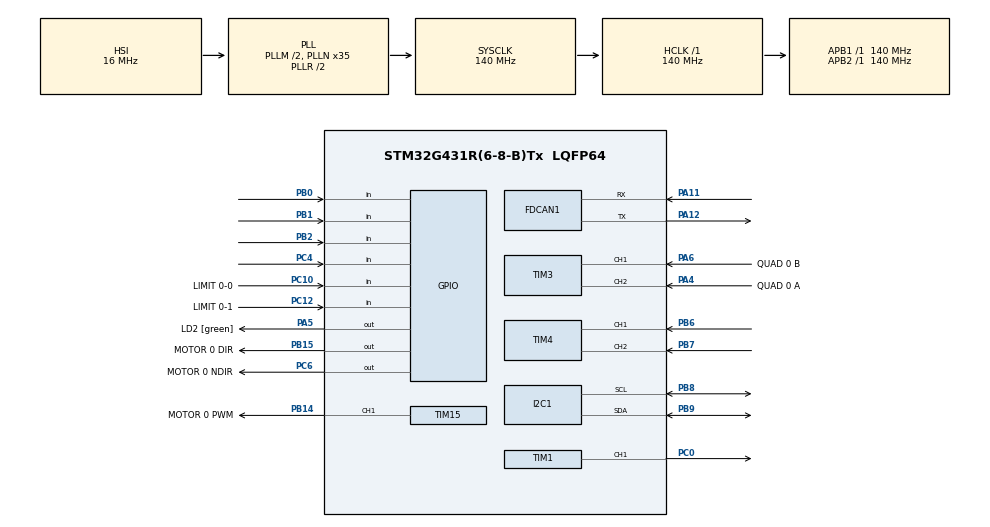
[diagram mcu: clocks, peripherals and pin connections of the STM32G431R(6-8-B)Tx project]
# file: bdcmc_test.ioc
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FDCAN1.CalculateBaudRateNominal=1000000
FDCAN1.CalculateTimeBitNominal=1000
FDCAN1.CalculateTimeQuantumNominal=7.142857142857143
FDCAN1.DataSyncJumpWidth=13
FDCAN1.DataTimeSeg1=14
FDCAN1.DataTimeSeg2=13
FDCAN1.FrameFormat=FDCAN_FRAME_FD_NO_BRS
FDCAN1.NominalPrescaler=1
FDCAN1.NominalSyncJumpWidth=19
FDCAN1.NominalTimeSeg1=120
FDCAN1.NominalTimeSeg2=19
I2C1.Timing=0x20B0CCFF
Mcu.Family=STM32G4
Mcu.Name=STM32G431R(6-8-B)Tx
Mcu.Package=LQFP64
NVIC.FDCAN1_IT0_IRQn=true\:0\:0\:false\:false\:true\:true\:true\:true
NVIC.I2C1_ER_IRQn=true\:0\:0\:false\:false\:true\:true\:true\:true
NVIC.I2C1_EV_IRQn=true\:0\:0\:false\:false\:true\:true\:true\:true
NVIC.PriorityGroup=NVIC_PRIORITYGROUP_4
NVIC.TIM1_TRG_COM_TIM17_IRQn=true\:0\:0\:false\:false\:true\:true\:true\:true
NVIC.TIM1_UP_TIM16_IRQn=true\:0\:0\:false\:false\:true\:true\:true\:true
NVIC.TIM3_IRQn=true\:0\:0\:false\:false\:true\:true\:true\:true
NVIC.TIM4_IRQn=true\:0\:0\:false\:false\:true\:true\:true\:true
NVIC.TIM6_DAC_IRQn=true\:0\:0\:false\:false\:true\:true\:true\:true
NVIC.TIM7_IRQn=true\:0\:0\:false\:false\:true\:true\:true\:true
PA11.Mode=FDCAN_Activate
PA11.Signal=FDCAN1_RX
PA12.Mode=FDCAN_Activate
PA12.Signal=FDCAN1_TX
PA13.GPIO_Label=T_SWDIO
PA13.Signal=SYS_JTMS-SWDIO
PA14.GPIO_Label=T_SWCLK
PA14.Signal=SYS_JTCK-SWCLK
PA2.GPIO_Label=LPUART1_TX [STLINKV3E_VCP_RX]
PA2.Signal=LPUART1_TX
PA3.GPIO_Label=LPUART1_RX [STLINKV3E_VCP_TX]
PA3.Signal=LPUART1_RX
PA4.GPIO_Label=QUAD 0 A
PA4.Signal=S_TIM3_CH2
PA5.GPIO_Label=LD2 [green]
PA5.Signal=GPIO_Output
PA6.GPIO_Label=QUAD 0 B
PA6.Signal=S_TIM3_CH1
PB0.Signal=GPIO_Input
PB1.Signal=GPIO_Input
PB14.GPIO_Label=MOTOR 0 PWM
PB14.Signal=S_TIM15_CH1
PB15.GPIO_Label=MOTOR 0 DIR
PB15.Signal=GPIO_Output
PB2.Signal=GPIO_Input
PB3.GPIO_Label=T_SWO
PB3.Signal=SYS_JTDO-SWO
PB6.Signal=S_TIM4_CH1
PB7.Signal=S_TIM4_CH2
PB8-BOOT0.Mode=I2C
PB8-BOOT0.Signal=I2C1_SCL
PB9.Mode=I2C
PB9.Signal=I2C1_SDA
PC0.Signal=S_TIM1_CH1
PC10.GPIO_Label=LIMIT 0-0
PC10.GPIO_PuPd=GPIO_PULLUP
PC10.Signal=GPIO_Input
PC12.GPIO_Label=LIMIT 0-1
PC12.GPIO_PuPd=GPIO_PULLUP
PC12.Signal=GPIO_Input
PC4.Signal=GPIO_Input
PC6.GPIO_Label=MOTOR 0 NDIR
PC6.Signal=GPIO_Output
PF1-OSC_OUT.Signal=RCC_OSC_OUT
ProjectManager.HeapSize=0x200
ProjectManager.StackSize=0x400
ProjectManager.TargetToolchain=STM32CubeIDE
RCC.ADC12Freq_Value=140000000
RCC.AHBFreq_Value=140000000
RCC.APB1Freq_Value=140000000
RCC.APB1TimFreq_Value=140000000
RCC.APB2Freq_Value=140000000
RCC.APB2TimFreq_Value=140000000
RCC.CortexFreq_Value=140000000
RCC.EXTERNAL_CLOCK_VALUE=12288000
RCC.HCLKFreq_Value=140000000
RCC.HSE_VALUE=24000000
RCC.HSI48_VALUE=48000000
RCC.HSI_VALUE=16000000
RCC.LSE_VALUE=32768
RCC.PLLM=RCC_PLLM_DIV2
RCC.PLLN=35
RCC.RTCClockSelection=RCC_RTCCLKSOURCE_LSE
RCC.SYSCLKFreq_VALUE=140000000
RCC.SYSCLKSource=RCC_SYSCLKSOURCE_PLLCLK
RCC.USBFreq_Value=140000000
RCC.VCOOutputFreq_Value=280000000
SH.S_TIM15_CH1.0=TIM15_CH1,PWM Generation1 CH1
SH.S_TIM1_CH1.0=TIM1_CH1,Output Compare1 CH1
SH.S_TIM3_CH1.0=TIM3_CH1,Encoder_Interface
SH.S_TIM3_CH2.0=TIM3_CH2,Encoder_Interface
SH.S_TIM4_CH1.0=TIM4_CH1,Encoder_Interface
SH.S_TIM4_CH2.0=TIM4_CH2,Encoder_Interface
TIM1.Channel-Output\ Compare1\ CH1=TIM_CHANNEL_1
TIM15.Channel-PWM\ Generation1\ CH1=TIM_CHANNEL_1
TIM15.PeriodNoDither=99
TIM15.Prescaler=63
TIM16.PeriodNoDither=54580
TIM16.Prescaler=512
TIM17.Channel=TIM_CHANNEL_1
TIM2.PeriodNoDither=58333
TIM2.Prescaler=119
TIM6.PeriodNoDither=13999
TIM7.PeriodNoDither=56000
TIM7.Prescaler=24
VP_SYS_VS_DBSignals.Mode=DisableDeadBatterySignals
VP_TIM16_VS_ClockSourceINT.Mode=Enable_Timer
VP_TIM17_VS_ClockSourceINT.Mode=Enable_Timer
VP_TIM17_VS_no_output1.Mode=Output Compare1 No Output
VP_TIM2_VS_ClockSourceINT.Mode=Internal
VP_TIM6_VS_ClockSourceINT.Mode=Enable_Timer
VP_TIM7_VS_ClockSourceINT.Mode=Enable_Timer
board=NUCLEO-G431RB

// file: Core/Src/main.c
/* USER CODE BEGIN Header */
/**
  ******************************************************************************
  * @file           : main.c
  * @brief          : Main program body
  ******************************************************************************
  * @attention
  *
  * Copyright (c) 2024 STMicroelectronics.
  * All rights reserved.
  *
  * This software is licensed under terms that can be found in the LICENSE file
  * in the root directory of this software component.
  * If no LICENSE file comes with this software, it is provided AS-IS.
  *
  ******************************************************************************
  */
/* USER CODE END Header */
#include "main.h"

FDCAN_HandleTypeDef hfdcan1;

I2C_HandleTypeDef hi2c1;

TIM_HandleTypeDef htim1;
TIM_HandleTypeDef htim2;
TIM_HandleTypeDef htim3;
TIM_HandleTypeDef htim4;
TIM_HandleTypeDef htim6;
TIM_HandleTypeDef htim7;
TIM_HandleTypeDef htim15;
TIM_HandleTypeDef htim16;
TIM_HandleTypeDef htim17;

void SystemClock_Config(void);
static void MX_GPIO_Init(void);
static void MX_FDCAN1_Init(void);
static void MX_I2C1_Init(void);
static void MX_TIM4_Init(void);
static void MX_TIM15_Init(void);
static void MX_TIM6_Init(void);
static void MX_TIM7_Init(void);
static void MX_TIM2_Init(void);
static void MX_TIM16_Init(void);
static void MX_TIM1_Init(void);
static void MX_TIM3_Init(void);
static void MX_TIM17_Init(void);
/* USER CODE BEGIN PFP */
void HAL_PostInit();
/* USER CODE END PFP */

int main(void)
{

  /* MCU Configuration--------------------------------------------------------*/

  /* Reset of all peripherals, Initializes the Flash interface and the Systick. */
  HAL_Init();

  /* Configure the system clock */
  SystemClock_Config();

  /* USER CODE BEGIN SysInit */
#ifdef VECT_TAB_SRAM
  SCB->VTOR = SRAM_BASE;
#else
  SCB->VTOR = FLASH_BASE;
#endif
  /* USER CODE END SysInit */

  /* Initialize all configured peripherals */
  MX_GPIO_Init();
  MX_FDCAN1_Init();
  MX_I2C1_Init();
  MX_TIM4_Init();
  MX_TIM15_Init();
  MX_TIM6_Init();
  MX_TIM7_Init();
  MX_TIM2_Init();
  MX_TIM16_Init();
  MX_TIM1_Init();
  MX_TIM3_Init();
  MX_TIM17_Init();
  /* USER CODE BEGIN 2 */
  HAL_PostInit();
  /* USER CODE END 2 */

  /* Infinite loop */
  while (1)
  {

  }
}

void SystemClock_Config(void)
{
  RCC_OscInitTypeDef RCC_OscInitStruct = {0};
  RCC_ClkInitTypeDef RCC_ClkInitStruct = {0};

  /** Configure the main internal regulator output voltage
  */
  HAL_PWREx_ControlVoltageScaling(PWR_REGULATOR_VOLTAGE_SCALE1);

  /** Initializes the RCC Oscillators according to the specified parameters
  * in the RCC_OscInitTypeDef structure.
  */
  RCC_OscInitStruct.OscillatorType = RCC_OSCILLATORTYPE_HSI;
  RCC_OscInitStruct.HSIState = RCC_HSI_ON;
  RCC_OscInitStruct.HSICalibrationValue = RCC_HSICALIBRATION_DEFAULT;
  RCC_OscInitStruct.PLL.PLLState = RCC_PLL_ON;
  RCC_OscInitStruct.PLL.PLLSource = RCC_PLLSOURCE_HSI;
  RCC_OscInitStruct.PLL.PLLM = RCC_PLLM_DIV2;
  RCC_OscInitStruct.PLL.PLLN = 35;
  RCC_OscInitStruct.PLL.PLLP = RCC_PLLP_DIV2;
  RCC_OscInitStruct.PLL.PLLQ = RCC_PLLQ_DIV2;
  RCC_OscInitStruct.PLL.PLLR = RCC_PLLR_DIV2;
  if (HAL_RCC_OscConfig(&RCC_OscInitStruct) != HAL_OK)
  {
    Error_Handler();
  }

  /** Initializes the CPU, AHB and APB buses clocks
  */
  RCC_ClkInitStruct.ClockType = RCC_CLOCKTYPE_HCLK|RCC_CLOCKTYPE_SYSCLK
                              |RCC_CLOCKTYPE_PCLK1|RCC_CLOCKTYPE_PCLK2;
  RCC_ClkInitStruct.SYSCLKSource = RCC_SYSCLKSOURCE_PLLCLK;
  RCC_ClkInitStruct.AHBCLKDivider = RCC_SYSCLK_DIV1;
  RCC_ClkInitStruct.APB1CLKDivider = RCC_HCLK_DIV1;
  RCC_ClkInitStruct.APB2CLKDivider = RCC_HCLK_DIV1;

  if (HAL_RCC_ClockConfig(&RCC_ClkInitStruct, FLASH_LATENCY_4) != HAL_OK)
  {
    Error_Handler();
  }
}

static void MX_FDCAN1_Init(void)
{

  hfdcan1.Instance = FDCAN1;
  hfdcan1.Init.ClockDivider = FDCAN_CLOCK_DIV1;
  hfdcan1.Init.FrameFormat = FDCAN_FRAME_FD_NO_BRS;
  hfdcan1.Init.Mode = FDCAN_MODE_NORMAL;
  hfdcan1.Init.AutoRetransmission = DISABLE;
  hfdcan1.Init.TransmitPause = DISABLE;
  hfdcan1.Init.ProtocolException = DISABLE;
  hfdcan1.Init.NominalPrescaler = 1;
  hfdcan1.Init.NominalSyncJumpWidth = 19;
  hfdcan1.Init.NominalTimeSeg1 = 120;
  hfdcan1.Init.NominalTimeSeg2 = 19;
  hfdcan1.Init.DataPrescaler = 1;
  hfdcan1.Init.DataSyncJumpWidth = 13;
  hfdcan1.Init.DataTimeSeg1 = 14;
  hfdcan1.Init.DataTimeSeg2 = 13;
  hfdcan1.Init.StdFiltersNbr = 0;
  hfdcan1.Init.ExtFiltersNbr = 0;
  hfdcan1.Init.TxFifoQueueMode = FDCAN_TX_FIFO_OPERATION;
  if (HAL_FDCAN_Init(&hfdcan1) != HAL_OK)
  {
    Error_Handler();
  }

}

static void MX_I2C1_Init(void)
{

  hi2c1.Instance = I2C1;
  hi2c1.Init.Timing = 0x20B0CCFF;
  hi2c1.Init.OwnAddress1 = 0;
  hi2c1.Init.AddressingMode = I2C_ADDRESSINGMODE_7BIT;
  hi2c1.Init.DualAddressMode = I2C_DUALADDRESS_DISABLE;
  hi2c1.Init.OwnAddress2 = 0;
  hi2c1.Init.OwnAddress2Masks = I2C_OA2_NOMASK;
  hi2c1.Init.GeneralCallMode = I2C_GENERALCALL_DISABLE;
  hi2c1.Init.NoStretchMode = I2C_NOSTRETCH_DISABLE;
  if (HAL_I2C_Init(&hi2c1) != HAL_OK)
  {
    Error_Handler();
  }

  /** Configure Analogue filter
  */
  if (HAL_I2CEx_ConfigAnalogFilter(&hi2c1, I2C_ANALOGFILTER_ENABLE) != HAL_OK)
  {
    Error_Handler();
  }

  /** Configure Digital filter
  */
  if (HAL_I2CEx_ConfigDigitalFilter(&hi2c1, 0) != HAL_OK)
  {
    Error_Handler();
  }

}

static void MX_TIM1_Init(void)
{

  TIM_MasterConfigTypeDef sMasterConfig = {0};
  TIM_OC_InitTypeDef sConfigOC = {0};
  TIM_BreakDeadTimeConfigTypeDef sBreakDeadTimeConfig = {0};

  htim1.Instance = TIM1;
  htim1.Init.Prescaler = 0;
  htim1.Init.CounterMode = TIM_COUNTERMODE_UP;
  htim1.Init.Period = 65535;
  htim1.Init.ClockDivision = TIM_CLOCKDIVISION_DIV1;
  htim1.Init.RepetitionCounter = 0;
  htim1.Init.AutoReloadPreload = TIM_AUTORELOAD_PRELOAD_DISABLE;
  if (HAL_TIM_OC_Init(&htim1) != HAL_OK)
  {
    Error_Handler();
  }
  sMasterConfig.MasterOutputTrigger = TIM_TRGO_RESET;
  sMasterConfig.MasterOutputTrigger2 = TIM_TRGO2_RESET;
  sMasterConfig.MasterSlaveMode = TIM_MASTERSLAVEMODE_DISABLE;
  if (HAL_TIMEx_MasterConfigSynchronization(&htim1, &sMasterConfig) != HAL_OK)
  {
    Error_Handler();
  }
  sConfigOC.OCMode = TIM_OCMODE_TIMING;
  sConfigOC.Pulse = 0;
  sConfigOC.OCPolarity = TIM_OCPOLARITY_HIGH;
  sConfigOC.OCNPolarity = TIM_OCNPOLARITY_HIGH;
  sConfigOC.OCFastMode = TIM_OCFAST_DISABLE;
  sConfigOC.OCIdleState = TIM_OCIDLESTATE_RESET;
  sConfigOC.OCNIdleState = TIM_OCNIDLESTATE_RESET;
  if (HAL_TIM_OC_ConfigChannel(&htim1, &sConfigOC, TIM_CHANNEL_1) != HAL_OK)
  {
    Error_Handler();
  }
  sBreakDeadTimeConfig.OffStateRunMode = TIM_OSSR_DISABLE;
  sBreakDeadTimeConfig.OffStateIDLEMode = TIM_OSSI_DISABLE;
  sBreakDeadTimeConfig.LockLevel = TIM_LOCKLEVEL_OFF;
  sBreakDeadTimeConfig.DeadTime = 0;
  sBreakDeadTimeConfig.BreakState = TIM_BREAK_DISABLE;
  sBreakDeadTimeConfig.BreakPolarity = TIM_BREAKPOLARITY_HIGH;
  sBreakDeadTimeConfig.BreakFilter = 0;
  sBreakDeadTimeConfig.BreakAFMode = TIM_BREAK_AFMODE_INPUT;
  sBreakDeadTimeConfig.Break2State = TIM_BREAK2_DISABLE;
  sBreakDeadTimeConfig.Break2Polarity = TIM_BREAK2POLARITY_HIGH;
  sBreakDeadTimeConfig.Break2Filter = 0;
  sBreakDeadTimeConfig.Break2AFMode = TIM_BREAK_AFMODE_INPUT;
  sBreakDeadTimeConfig.AutomaticOutput = TIM_AUTOMATICOUTPUT_DISABLE;
  if (HAL_TIMEx_ConfigBreakDeadTime(&htim1, &sBreakDeadTimeConfig) != HAL_OK)
  {
    Error_Handler();
  }
  HAL_TIM_MspPostInit(&htim1);

}

static void MX_TIM2_Init(void)
{

  TIM_ClockConfigTypeDef sClockSourceConfig = {0};
  TIM_MasterConfigTypeDef sMasterConfig = {0};

  htim2.Instance = TIM2;
  htim2.Init.Prescaler = 119;
  htim2.Init.CounterMode = TIM_COUNTERMODE_UP;
  htim2.Init.Period = 58333;
  htim2.Init.ClockDivision = TIM_CLOCKDIVISION_DIV1;
  htim2.Init.AutoReloadPreload = TIM_AUTORELOAD_PRELOAD_DISABLE;
  if (HAL_TIM_Base_Init(&htim2) != HAL_OK)
  {
    Error_Handler();
  }
  sClockSourceConfig.ClockSource = TIM_CLOCKSOURCE_INTERNAL;
  if (HAL_TIM_ConfigClockSource(&htim2, &sClockSourceConfig) != HAL_OK)
  {
    Error_Handler();
  }
  sMasterConfig.MasterOutputTrigger = TIM_TRGO_RESET;
  sMasterConfig.MasterSlaveMode = TIM_MASTERSLAVEMODE_DISABLE;
  if (HAL_TIMEx_MasterConfigSynchronization(&htim2, &sMasterConfig) != HAL_OK)
  {
    Error_Handler();
  }

}

static void MX_TIM3_Init(void)
{

  TIM_Encoder_InitTypeDef sConfig = {0};
  TIM_MasterConfigTypeDef sMasterConfig = {0};

  htim3.Instance = TIM3;
  htim3.Init.Prescaler = 0;
  htim3.Init.CounterMode = TIM_COUNTERMODE_UP;
  htim3.Init.Period = 65535;
  htim3.Init.ClockDivision = TIM_CLOCKDIVISION_DIV1;
  htim3.Init.AutoReloadPreload = TIM_AUTORELOAD_PRELOAD_DISABLE;
  sConfig.EncoderMode = TIM_ENCODERMODE_TI1;
  sConfig.IC1Polarity = TIM_ICPOLARITY_RISING;
  sConfig.IC1Selection = TIM_ICSELECTION_DIRECTTI;
  sConfig.IC1Prescaler = TIM_ICPSC_DIV1;
  sConfig.IC1Filter = 0;
  sConfig.IC2Polarity = TIM_ICPOLARITY_RISING;
  sConfig.IC2Selection = TIM_ICSELECTION_DIRECTTI;
  sConfig.IC2Prescaler = TIM_ICPSC_DIV1;
  sConfig.IC2Filter = 0;
  if (HAL_TIM_Encoder_Init(&htim3, &sConfig) != HAL_OK)
  {
    Error_Handler();
  }
  sMasterConfig.MasterOutputTrigger = TIM_TRGO_RESET;
  sMasterConfig.MasterSlaveMode = TIM_MASTERSLAVEMODE_DISABLE;
  if (HAL_TIMEx_MasterConfigSynchronization(&htim3, &sMasterConfig) != HAL_OK)
  {
    Error_Handler();
  }

}

static void MX_TIM4_Init(void)
{

  TIM_Encoder_InitTypeDef sConfig = {0};
  TIM_MasterConfigTypeDef sMasterConfig = {0};

  htim4.Instance = TIM4;
  htim4.Init.Prescaler = 0;
  htim4.Init.CounterMode = TIM_COUNTERMODE_UP;
  htim4.Init.Period = 65535;
  htim4.Init.ClockDivision = TIM_CLOCKDIVISION_DIV1;
  htim4.Init.AutoReloadPreload = TIM_AUTORELOAD_PRELOAD_DISABLE;
  sConfig.EncoderMode = TIM_ENCODERMODE_TI1;
  sConfig.IC1Polarity = TIM_ICPOLARITY_RISING;
  sConfig.IC1Selection = TIM_ICSELECTION_DIRECTTI;
  sConfig.IC1Prescaler = TIM_ICPSC_DIV1;
  sConfig.IC1Filter = 0;
  sConfig.IC2Polarity = TIM_ICPOLARITY_RISING;
  sConfig.IC2Selection = TIM_ICSELECTION_DIRECTTI;
  sConfig.IC2Prescaler = TIM_ICPSC_DIV1;
  sConfig.IC2Filter = 0;
  if (HAL_TIM_Encoder_Init(&htim4, &sConfig) != HAL_OK)
  {
    Error_Handler();
  }
  sMasterConfig.MasterOutputTrigger = TIM_TRGO_RESET;
  sMasterConfig.MasterSlaveMode = TIM_MASTERSLAVEMODE_DISABLE;
  if (HAL_TIMEx_MasterConfigSynchronization(&htim4, &sMasterConfig) != HAL_OK)
  {
    Error_Handler();
  }

}

static void MX_TIM6_Init(void)
{

  TIM_MasterConfigTypeDef sMasterConfig = {0};

  htim6.Instance = TIM6;
  htim6.Init.Prescaler = 0;
  htim6.Init.CounterMode = TIM_COUNTERMODE_UP;
  htim6.Init.Period = 13999;
  htim6.Init.AutoReloadPreload = TIM_AUTORELOAD_PRELOAD_DISABLE;
  if (HAL_TIM_Base_Init(&htim6) != HAL_OK)
  {
    Error_Handler();
  }
  sMasterConfig.MasterOutputTrigger = TIM_TRGO_RESET;
  sMasterConfig.MasterSlaveMode = TIM_MASTERSLAVEMODE_DISABLE;
  if (HAL_TIMEx_MasterConfigSynchronization(&htim6, &sMasterConfig) != HAL_OK)
  {
    Error_Handler();
  }

}

static void MX_TIM7_Init(void)
{

  TIM_MasterConfigTypeDef sMasterConfig = {0};

  htim7.Instance = TIM7;
  htim7.Init.Prescaler = 24;
  htim7.Init.CounterMode = TIM_COUNTERMODE_UP;
  htim7.Init.Period = 56000;
  htim7.Init.AutoReloadPreload = TIM_AUTORELOAD_PRELOAD_DISABLE;
  if (HAL_TIM_Base_Init(&htim7) != HAL_OK)
  {
    Error_Handler();
  }
  sMasterConfig.MasterOutputTrigger = TIM_TRGO_RESET;
  sMasterConfig.MasterSlaveMode = TIM_MASTERSLAVEMODE_DISABLE;
  if (HAL_TIMEx_MasterConfigSynchronization(&htim7, &sMasterConfig) != HAL_OK)
  {
    Error_Handler();
  }

}

static void MX_TIM15_Init(void)
{

  TIM_MasterConfigTypeDef sMasterConfig = {0};
  TIM_OC_InitTypeDef sConfigOC = {0};
  TIM_BreakDeadTimeConfigTypeDef sBreakDeadTimeConfig = {0};

  htim15.Instance = TIM15;
  htim15.Init.Prescaler = 63;
  htim15.Init.CounterMode = TIM_COUNTERMODE_UP;
  htim15.Init.Period = 99;
  htim15.Init.ClockDivision = TIM_CLOCKDIVISION_DIV1;
  htim15.Init.RepetitionCounter = 0;
  htim15.Init.AutoReloadPreload = TIM_AUTORELOAD_PRELOAD_DISABLE;
  if (HAL_TIM_PWM_Init(&htim15) != HAL_OK)
  {
    Error_Handler();
  }
  sMasterConfig.MasterOutputTrigger = TIM_TRGO_RESET;
  sMasterConfig.MasterSlaveMode = TIM_MASTERSLAVEMODE_DISABLE;
  if (HAL_TIMEx_MasterConfigSynchronization(&htim15, &sMasterConfig) != HAL_OK)
  {
    Error_Handler();
  }
  sConfigOC.OCMode = TIM_OCMODE_PWM1;
  sConfigOC.Pulse = 0;
  sConfigOC.OCPolarity = TIM_OCPOLARITY_HIGH;
  sConfigOC.OCNPolarity = TIM_OCNPOLARITY_HIGH;
  sConfigOC.OCFastMode = TIM_OCFAST_DISABLE;
  sConfigOC.OCIdleState = TIM_OCIDLESTATE_RESET;
  sConfigOC.OCNIdleState = TIM_OCNIDLESTATE_RESET;
  if (HAL_TIM_PWM_ConfigChannel(&htim15, &sConfigOC, TIM_CHANNEL_1) != HAL_OK)
  {
    Error_Handler();
  }
  sBreakDeadTimeConfig.OffStateRunMode = TIM_OSSR_DISABLE;
  sBreakDeadTimeConfig.OffStateIDLEMode = TIM_OSSI_DISABLE;
  sBreakDeadTimeConfig.LockLevel = TIM_LOCKLEVEL_OFF;
  sBreakDeadTimeConfig.DeadTime = 0;
  sBreakDeadTimeConfig.BreakState = TIM_BREAK_DISABLE;
  sBreakDeadTimeConfig.BreakPolarity = TIM_BREAKPOLARITY_HIGH;
  sBreakDeadTimeConfig.BreakFilter = 0;
  sBreakDeadTimeConfig.AutomaticOutput = TIM_AUTOMATICOUTPUT_DISABLE;
  if (HAL_TIMEx_ConfigBreakDeadTime(&htim15, &sBreakDeadTimeConfig) != HAL_OK)
  {
    Error_Handler();
  }
  HAL_TIM_MspPostInit(&htim15);

}

static void MX_TIM16_Init(void)
{

  htim16.Instance = TIM16;
  htim16.Init.Prescaler = 512;
  htim16.Init.CounterMode = TIM_COUNTERMODE_UP;
  htim16.Init.Period = 54580;
  htim16.Init.ClockDivision = TIM_CLOCKDIVISION_DIV1;
  htim16.Init.RepetitionCounter = 0;
  htim16.Init.AutoReloadPreload = TIM_AUTORELOAD_PRELOAD_DISABLE;
  if (HAL_TIM_Base_Init(&htim16) != HAL_OK)
  {
    Error_Handler();
  }

}

static void MX_TIM17_Init(void)
{

  TIM_OC_InitTypeDef sConfigOC = {0};
  TIM_BreakDeadTimeConfigTypeDef sBreakDeadTimeConfig = {0};

  htim17.Instance = TIM17;
  htim17.Init.Prescaler = 0;
  htim17.Init.CounterMode = TIM_COUNTERMODE_UP;
  htim17.Init.Period = 65535;
  htim17.Init.ClockDivision = TIM_CLOCKDIVISION_DIV1;
  htim17.Init.RepetitionCounter = 0;
  htim17.Init.AutoReloadPreload = TIM_AUTORELOAD_PRELOAD_DISABLE;
  if (HAL_TIM_Base_Init(&htim17) != HAL_OK)
  {
    Error_Handler();
  }
  if (HAL_TIM_OC_Init(&htim17) != HAL_OK)
  {
    Error_Handler();
  }
  sConfigOC.OCMode = TIM_OCMODE_TIMING;
  sConfigOC.Pulse = 0;
  sConfigOC.OCPolarity = TIM_OCPOLARITY_HIGH;
  sConfigOC.OCNPolarity = TIM_OCNPOLARITY_HIGH;
  sConfigOC.OCFastMode = TIM_OCFAST_DISABLE;
  sConfigOC.OCIdleState = TIM_OCIDLESTATE_RESET;
  sConfigOC.OCNIdleState = TIM_OCNIDLESTATE_RESET;
  if (HAL_TIM_OC_ConfigChannel(&htim17, &sConfigOC, TIM_CHANNEL_1) != HAL_OK)
  {
    Error_Handler();
  }
  sBreakDeadTimeConfig.OffStateRunMode = TIM_OSSR_DISABLE;
  sBreakDeadTimeConfig.OffStateIDLEMode = TIM_OSSI_DISABLE;
  sBreakDeadTimeConfig.LockLevel = TIM_LOCKLEVEL_OFF;
  sBreakDeadTimeConfig.DeadTime = 0;
  sBreakDeadTimeConfig.BreakState = TIM_BREAK_DISABLE;
  sBreakDeadTimeConfig.BreakPolarity = TIM_BREAKPOLARITY_HIGH;
  sBreakDeadTimeConfig.BreakFilter = 0;
  sBreakDeadTimeConfig.AutomaticOutput = TIM_AUTOMATICOUTPUT_DISABLE;
  if (HAL_TIMEx_ConfigBreakDeadTime(&htim17, &sBreakDeadTimeConfig) != HAL_OK)
  {
    Error_Handler();
  }

}

static void MX_GPIO_Init(void)
{
  GPIO_InitTypeDef GPIO_InitStruct = {0};

  /* GPIO Ports Clock Enable */
  __HAL_RCC_GPIOF_CLK_ENABLE();
  __HAL_RCC_GPIOC_CLK_ENABLE();
  __HAL_RCC_GPIOA_CLK_ENABLE();
  __HAL_RCC_GPIOB_CLK_ENABLE();

  /*Configure GPIO pin Output Level */
  HAL_GPIO_WritePin(LD2_GPIO_Port, LD2_Pin, GPIO_PIN_RESET);

  /*Configure GPIO pin Output Level */
  HAL_GPIO_WritePin(MOTOR_0_DIR_GPIO_Port, MOTOR_0_DIR_Pin, GPIO_PIN_RESET);

  /*Configure GPIO pin Output Level */
  HAL_GPIO_WritePin(MOTOR_0_NDIR_GPIO_Port, MOTOR_0_NDIR_Pin, GPIO_PIN_RESET);

  /*Configure GPIO pins : LPUART1_TX_Pin LPUART1_RX_Pin */
  GPIO_InitStruct.Pin = LPUART1_TX_Pin|LPUART1_RX_Pin;
  GPIO_InitStruct.Mode = GPIO_MODE_AF_PP;
  GPIO_InitStruct.Pull = GPIO_NOPULL;
  GPIO_InitStruct.Speed = GPIO_SPEED_FREQ_LOW;
  GPIO_InitStruct.Alternate = GPIO_AF12_LPUART1;
  HAL_GPIO_Init(GPIOA, &GPIO_InitStruct);

  /*Configure GPIO pin : LD2_Pin */
  GPIO_InitStruct.Pin = LD2_Pin;
  GPIO_InitStruct.Mode = GPIO_MODE_OUTPUT_PP;
  GPIO_InitStruct.Pull = GPIO_NOPULL;
  GPIO_InitStruct.Speed = GPIO_SPEED_FREQ_LOW;
  HAL_GPIO_Init(LD2_GPIO_Port, &GPIO_InitStruct);

  /*Configure GPIO pin : PC4 */
  GPIO_InitStruct.Pin = GPIO_PIN_4;
  GPIO_InitStruct.Mode = GPIO_MODE_INPUT;
  GPIO_InitStruct.Pull = GPIO_NOPULL;
  HAL_GPIO_Init(GPIOC, &GPIO_InitStruct);

  /*Configure GPIO pins : PB0 PB1 PB2 */
  GPIO_InitStruct.Pin = GPIO_PIN_0|GPIO_PIN_1|GPIO_PIN_2;
  GPIO_InitStruct.Mode = GPIO_MODE_INPUT;
  GPIO_InitStruct.Pull = GPIO_NOPULL;
  HAL_GPIO_Init(GPIOB, &GPIO_InitStruct);

  /*Configure GPIO pin : MOTOR_0_DIR_Pin */
  GPIO_InitStruct.Pin = MOTOR_0_DIR_Pin;
  GPIO_InitStruct.Mode = GPIO_MODE_OUTPUT_PP;
  GPIO_InitStruct.Pull = GPIO_NOPULL;
  GPIO_InitStruct.Speed = GPIO_SPEED_FREQ_LOW;
  HAL_GPIO_Init(MOTOR_0_DIR_GPIO_Port, &GPIO_InitStruct);

  /*Configure GPIO pin : MOTOR_0_NDIR_Pin */
  GPIO_InitStruct.Pin = MOTOR_0_NDIR_Pin;
  GPIO_InitStruct.Mode = GPIO_MODE_OUTPUT_PP;
  GPIO_InitStruct.Pull = GPIO_NOPULL;
  GPIO_InitStruct.Speed = GPIO_SPEED_FREQ_LOW;
  HAL_GPIO_Init(MOTOR_0_NDIR_GPIO_Port, &GPIO_InitStruct);

  /*Configure GPIO pins : LIMIT_0_0_Pin LIMIT_0_1_Pin */
  GPIO_InitStruct.Pin = LIMIT_0_0_Pin|LIMIT_0_1_Pin;
  GPIO_InitStruct.Mode = GPIO_MODE_INPUT;
  GPIO_InitStruct.Pull = GPIO_PULLUP;
  HAL_GPIO_Init(GPIOC, &GPIO_InitStruct);

}

void Error_Handler(void)
{
  __disable_irq();
  while (1)
  {
  }
}
